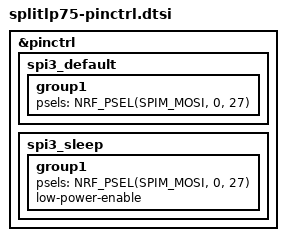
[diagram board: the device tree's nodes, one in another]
/*
 * Copyright (c) 2024 Andrew Kannan
 * SPDX-License-Identifier: MIT
 */

&pinctrl {
    spi3_default: spi3_default {
        group1 {
            psels = <NRF_PSEL(SPIM_MOSI, 0, 27)>;
        };
    };
    spi3_sleep: spi3_sleep {
        group1 {
            psels = <NRF_PSEL(SPIM_MOSI, 0, 27)>;
            low-power-enable;
        };
    };
};
